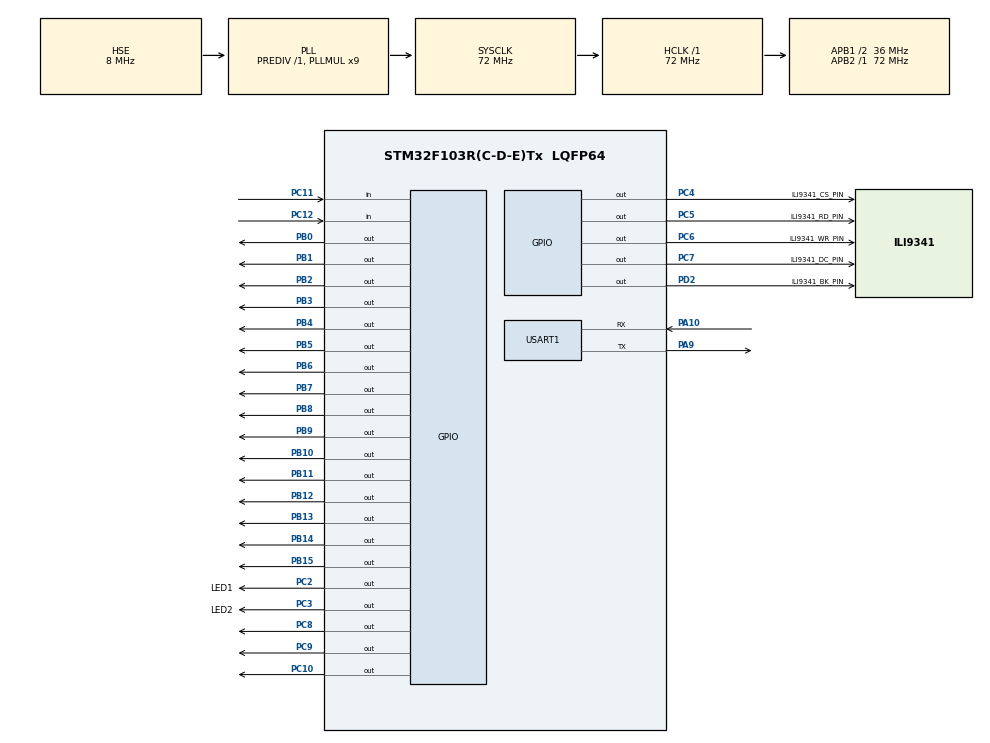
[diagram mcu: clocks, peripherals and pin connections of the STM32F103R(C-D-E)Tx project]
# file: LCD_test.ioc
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Mcu.Family=STM32F1
Mcu.Name=STM32F103R(C-D-E)Tx
Mcu.Package=LQFP64
NVIC.PriorityGroup=NVIC_PRIORITYGROUP_4
PA10.Mode=Asynchronous
PA10.Signal=USART1_RX
PA13.Mode=Serial_Wire
PA13.Signal=SYS_JTMS-SWDIO
PA14.Mode=Serial_Wire
PA14.Signal=SYS_JTCK-SWCLK
PA9.Mode=Asynchronous
PA9.Signal=USART1_TX
PB0.GPIO_Speed=GPIO_SPEED_FREQ_HIGH
PB0.Signal=GPIO_Output
PB1.GPIO_Speed=GPIO_SPEED_FREQ_HIGH
PB1.Signal=GPIO_Output
PB10.GPIO_Speed=GPIO_SPEED_FREQ_HIGH
PB10.Signal=GPIO_Output
PB11.GPIO_Speed=GPIO_SPEED_FREQ_HIGH
PB11.Signal=GPIO_Output
PB12.GPIO_Speed=GPIO_SPEED_FREQ_HIGH
PB12.Signal=GPIO_Output
PB13.GPIO_Speed=GPIO_SPEED_FREQ_HIGH
PB13.Signal=GPIO_Output
PB14.GPIO_Speed=GPIO_SPEED_FREQ_HIGH
PB14.Signal=GPIO_Output
PB15.GPIO_Speed=GPIO_SPEED_FREQ_HIGH
PB15.Signal=GPIO_Output
PB2.GPIO_Speed=GPIO_SPEED_FREQ_HIGH
PB2.Signal=GPIO_Output
PB3.GPIO_Speed=GPIO_SPEED_FREQ_HIGH
PB3.Signal=GPIO_Output
PB4.GPIO_Speed=GPIO_SPEED_FREQ_HIGH
PB4.Signal=GPIO_Output
PB5.GPIO_Speed=GPIO_SPEED_FREQ_HIGH
PB5.Signal=GPIO_Output
PB6.GPIO_Speed=GPIO_SPEED_FREQ_HIGH
PB6.Signal=GPIO_Output
PB7.GPIO_Speed=GPIO_SPEED_FREQ_HIGH
PB7.Signal=GPIO_Output
PB8.GPIO_Speed=GPIO_SPEED_FREQ_HIGH
PB8.Signal=GPIO_Output
PB9.GPIO_Speed=GPIO_SPEED_FREQ_HIGH
PB9.Signal=GPIO_Output
PC10.GPIO_Speed=GPIO_SPEED_FREQ_HIGH
PC10.Signal=GPIO_Output
PC11.GPIO_Mode=GPIO_MODE_INPUT
PC11.GPIO_PuPd=GPIO_PULLUP
PC11.Signal=GPIO_Input
PC12.GPIO_PuPd=GPIO_PULLUP
PC12.Signal=GPIO_Input
PC2.GPIO_Label=LED1
PC2.GPIO_Speed=GPIO_SPEED_FREQ_HIGH
PC2.Signal=GPIO_Output
PC3.GPIO_Label=LED2
PC3.GPIO_Speed=GPIO_SPEED_FREQ_HIGH
PC3.Signal=GPIO_Output
PC4.GPIO_Label=ILI9341_CS_PIN
PC4.GPIO_Speed=GPIO_SPEED_FREQ_HIGH
PC4.Signal=GPIO_Output
PC5.GPIO_Label=ILI9341_RD_PIN
PC5.GPIO_Speed=GPIO_SPEED_FREQ_HIGH
PC5.Signal=GPIO_Output
PC6.GPIO_Label=ILI9341_WR_PIN
PC6.GPIO_Speed=GPIO_SPEED_FREQ_HIGH
PC6.Signal=GPIO_Output
PC7.GPIO_Label=ILI9341_DC_PIN
PC7.GPIO_Speed=GPIO_SPEED_FREQ_HIGH
PC7.Signal=GPIO_Output
PC8.GPIO_Speed=GPIO_SPEED_FREQ_HIGH
PC8.Signal=GPIO_Output
PC9.GPIO_Speed=GPIO_SPEED_FREQ_HIGH
PC9.Signal=GPIO_Output
PD0-OSC_IN.Mode=HSE-External-Oscillator
PD0-OSC_IN.Signal=RCC_OSC_IN
PD1-OSC_OUT.Mode=HSE-External-Oscillator
PD1-OSC_OUT.Signal=RCC_OSC_OUT
PD2.GPIO_Label=ILI9341_BK_PIN
PD2.GPIO_Speed=GPIO_SPEED_FREQ_HIGH
PD2.Signal=GPIO_Output
ProjectManager.HeapSize=0x200
ProjectManager.StackSize=0x400
ProjectManager.TargetToolchain=SW4STM32
RCC.AHBFreq_Value=72000000
RCC.APB1CLKDivider=RCC_HCLK_DIV2
RCC.APB1Freq_Value=36000000
RCC.APB1TimFreq_Value=72000000
RCC.APB2Freq_Value=72000000
RCC.APB2TimFreq_Value=72000000
RCC.HCLKFreq_Value=72000000
RCC.PLLMUL=RCC_PLL_MUL9
RCC.PLLSourceVirtual=RCC_PLLSOURCE_HSE
RCC.SYSCLKFreq_VALUE=72000000
RCC.SYSCLKSource=RCC_SYSCLKSOURCE_PLLCLK
RCC.USBFreq_Value=72000000
USART1.VirtualMode=VM_ASYNC
board=custom

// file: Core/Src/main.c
/* USER CODE BEGIN Header */
/**
  ******************************************************************************
  * @file           : main.c
  * @brief          : Main program body
  ******************************************************************************
  * @attention
  *
  * <h2><center>&copy; Copyright (c) 2022 STMicroelectronics.
  * All rights reserved.</center></h2>
  *
  * This software component is licensed by ST under BSD 3-Clause license,
  * the "License"; You may not use this file except in compliance with the
  * License. You may obtain a copy of the License at:
  *                        opensource.org/licenses/BSD-3-Clause
  *
  ******************************************************************************
  */
/* USER CODE END Header */
#include "main.h"

/* USER CODE BEGIN Includes */
#include "led.h"
/* USER CODE END Includes */

UART_HandleTypeDef huart1;

void SystemClock_Config(void);
static void MX_GPIO_Init(void);
static void MX_USART1_UART_Init(void);

int main(void)
{

  /* MCU Configuration--------------------------------------------------------*/

  /* Reset of all peripherals, Initializes the Flash interface and the Systick. */
  HAL_Init();

  /* Configure the system clock */
  SystemClock_Config();

  /* Initialize all configured peripherals */
  MX_GPIO_Init();
  MX_USART1_UART_Init();
  /* USER CODE BEGIN 2 */
  RetargetInit(&huart1);
  printf("LCD_test\r\n");
  running_water_led();
  /* USER CODE END 2 */

  /* Infinite loop */
  while (1)
  {

  }
}

void SystemClock_Config(void)
{
  RCC_OscInitTypeDef RCC_OscInitStruct = {0};
  RCC_ClkInitTypeDef RCC_ClkInitStruct = {0};

  /** Initializes the RCC Oscillators according to the specified parameters
  * in the RCC_OscInitTypeDef structure.
  */
  RCC_OscInitStruct.OscillatorType = RCC_OSCILLATORTYPE_HSE;
  RCC_OscInitStruct.HSEState = RCC_HSE_ON;
  RCC_OscInitStruct.HSEPredivValue = RCC_HSE_PREDIV_DIV1;
  RCC_OscInitStruct.HSIState = RCC_HSI_ON;
  RCC_OscInitStruct.PLL.PLLState = RCC_PLL_ON;
  RCC_OscInitStruct.PLL.PLLSource = RCC_PLLSOURCE_HSE;
  RCC_OscInitStruct.PLL.PLLMUL = RCC_PLL_MUL9;
  if (HAL_RCC_OscConfig(&RCC_OscInitStruct) != HAL_OK)
  {
    Error_Handler();
  }
  /** Initializes the CPU, AHB and APB buses clocks
  */
  RCC_ClkInitStruct.ClockType = RCC_CLOCKTYPE_HCLK|RCC_CLOCKTYPE_SYSCLK
                              |RCC_CLOCKTYPE_PCLK1|RCC_CLOCKTYPE_PCLK2;
  RCC_ClkInitStruct.SYSCLKSource = RCC_SYSCLKSOURCE_PLLCLK;
  RCC_ClkInitStruct.AHBCLKDivider = RCC_SYSCLK_DIV1;
  RCC_ClkInitStruct.APB1CLKDivider = RCC_HCLK_DIV2;
  RCC_ClkInitStruct.APB2CLKDivider = RCC_HCLK_DIV1;

  if (HAL_RCC_ClockConfig(&RCC_ClkInitStruct, FLASH_LATENCY_2) != HAL_OK)
  {
    Error_Handler();
  }
}

static void MX_USART1_UART_Init(void)
{

  huart1.Instance = USART1;
  huart1.Init.BaudRate = 115200;
  huart1.Init.WordLength = UART_WORDLENGTH_8B;
  huart1.Init.StopBits = UART_STOPBITS_1;
  huart1.Init.Parity = UART_PARITY_NONE;
  huart1.Init.Mode = UART_MODE_TX_RX;
  huart1.Init.HwFlowCtl = UART_HWCONTROL_NONE;
  huart1.Init.OverSampling = UART_OVERSAMPLING_16;
  if (HAL_UART_Init(&huart1) != HAL_OK)
  {
    Error_Handler();
  }

}

static void MX_GPIO_Init(void)
{
  GPIO_InitTypeDef GPIO_InitStruct = {0};

  /* GPIO Ports Clock Enable */
  __HAL_RCC_GPIOD_CLK_ENABLE();
  __HAL_RCC_GPIOC_CLK_ENABLE();
  __HAL_RCC_GPIOB_CLK_ENABLE();
  __HAL_RCC_GPIOA_CLK_ENABLE();

  /*Configure GPIO pin Output Level */
  HAL_GPIO_WritePin(GPIOC, LED1_Pin|LED2_Pin|ILI9341_CS_PIN_Pin|ILI9341_RD_PIN_Pin
                          |ILI9341_WR_PIN_Pin|ILI9341_DC_PIN_Pin|GPIO_PIN_8|GPIO_PIN_9
                          |GPIO_PIN_10, GPIO_PIN_RESET);

  /*Configure GPIO pin Output Level */
  HAL_GPIO_WritePin(GPIOB, GPIO_PIN_0|GPIO_PIN_1|GPIO_PIN_2|GPIO_PIN_10
                          |GPIO_PIN_11|GPIO_PIN_12|GPIO_PIN_13|GPIO_PIN_14
                          |GPIO_PIN_15|GPIO_PIN_3|GPIO_PIN_4|GPIO_PIN_5
                          |GPIO_PIN_6|GPIO_PIN_7|GPIO_PIN_8|GPIO_PIN_9, GPIO_PIN_RESET);

  /*Configure GPIO pin Output Level */
  HAL_GPIO_WritePin(ILI9341_BK_PIN_GPIO_Port, ILI9341_BK_PIN_Pin, GPIO_PIN_RESET);

  /*Configure GPIO pins : LED1_Pin LED2_Pin ILI9341_CS_PIN_Pin ILI9341_RD_PIN_Pin
                           ILI9341_WR_PIN_Pin ILI9341_DC_PIN_Pin PC8 PC9
                           PC10 */
  GPIO_InitStruct.Pin = LED1_Pin|LED2_Pin|ILI9341_CS_PIN_Pin|ILI9341_RD_PIN_Pin
                          |ILI9341_WR_PIN_Pin|ILI9341_DC_PIN_Pin|GPIO_PIN_8|GPIO_PIN_9
                          |GPIO_PIN_10;
  GPIO_InitStruct.Mode = GPIO_MODE_OUTPUT_PP;
  GPIO_InitStruct.Pull = GPIO_NOPULL;
  GPIO_InitStruct.Speed = GPIO_SPEED_FREQ_HIGH;
  HAL_GPIO_Init(GPIOC, &GPIO_InitStruct);

  /*Configure GPIO pins : PB0 PB1 PB2 PB10
                           PB11 PB12 PB13 PB14
                           PB15 PB3 PB4 PB5
                           PB6 PB7 PB8 PB9 */
  GPIO_InitStruct.Pin = GPIO_PIN_0|GPIO_PIN_1|GPIO_PIN_2|GPIO_PIN_10
                          |GPIO_PIN_11|GPIO_PIN_12|GPIO_PIN_13|GPIO_PIN_14
                          |GPIO_PIN_15|GPIO_PIN_3|GPIO_PIN_4|GPIO_PIN_5
                          |GPIO_PIN_6|GPIO_PIN_7|GPIO_PIN_8|GPIO_PIN_9;
  GPIO_InitStruct.Mode = GPIO_MODE_OUTPUT_PP;
  GPIO_InitStruct.Pull = GPIO_NOPULL;
  GPIO_InitStruct.Speed = GPIO_SPEED_FREQ_HIGH;
  HAL_GPIO_Init(GPIOB, &GPIO_InitStruct);

  /*Configure GPIO pins : PC11 PC12 */
  GPIO_InitStruct.Pin = GPIO_PIN_11|GPIO_PIN_12;
  GPIO_InitStruct.Mode = GPIO_MODE_INPUT;
  GPIO_InitStruct.Pull = GPIO_PULLUP;
  HAL_GPIO_Init(GPIOC, &GPIO_InitStruct);

  /*Configure GPIO pin : ILI9341_BK_PIN_Pin */
  GPIO_InitStruct.Pin = ILI9341_BK_PIN_Pin;
  GPIO_InitStruct.Mode = GPIO_MODE_OUTPUT_PP;
  GPIO_InitStruct.Pull = GPIO_NOPULL;
  GPIO_InitStruct.Speed = GPIO_SPEED_FREQ_HIGH;
  HAL_GPIO_Init(ILI9341_BK_PIN_GPIO_Port, &GPIO_InitStruct);

}

void Error_Handler(void)
{
  __disable_irq();
  while (1)
  {
  }
}

/************************ (C) COPYRIGHT STMicroelectronics *****END OF FILE****/
